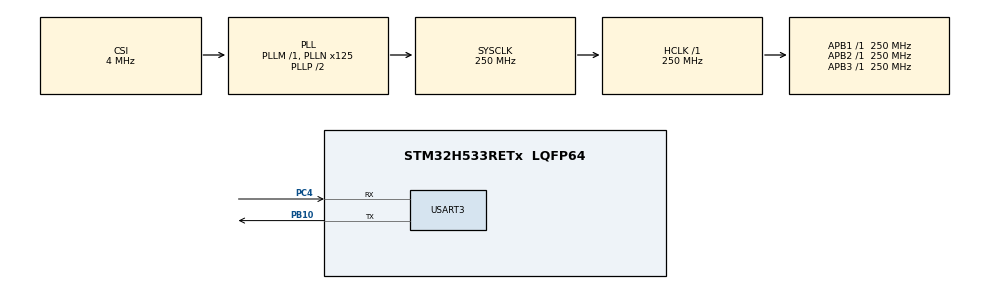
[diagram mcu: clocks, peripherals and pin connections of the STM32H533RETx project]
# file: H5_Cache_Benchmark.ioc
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CORTEX_M33_NS.userName=CORTEX_M33
Mcu.Family=STM32H5
Mcu.Name=STM32H533RETx
Mcu.Package=LQFP64
NUCLEO-H533RE.BUTTON=1
NUCLEO-H533RE.LD4=true
NUCLEO-H533RE.VCP=true
NVIC.EXTI13_IRQn=true\:0\:0\:false\:false\:true\:false\:true\:true
NVIC.PriorityGroup=NVIC_PRIORITYGROUP_4
PA13(JTMS/SWDIO).GPIO_Label=SWDIO
PA13(JTMS/SWDIO).Signal=DEBUG_JTMS-SWDIO
PA14(JTCK/SWCLK).GPIO_Label=SWCLK
PA14(JTCK/SWCLK).Signal=DEBUG_JTCK-SWCLK
PA15(JTDI).GPIO_Label=JTDI
PA15(JTDI).Signal=DEBUG_JTDI
PA2.Signal=USART2_TX
PA3.Signal=USART2_RX
PB10.Mode=Asynchronous
PB10.Signal=USART3_TX
PB3(JTDO/TRACESWO).GPIO_Label=SWO
PB3(JTDO/TRACESWO).Signal=DEBUG_JTDO-SWO
PC4.Mode=Asynchronous
PC4.Signal=USART3_RX
PH0-OSC_IN(PH0).Mode=HSE-External-Oscillator
PH0-OSC_IN(PH0).Signal=RCC_OSC_IN
PH1-OSC_OUT(PH1).Mode=HSE-External-Oscillator
PH1-OSC_OUT(PH1).Signal=RCC_OSC_OUT
ProjectManager.HeapSize=0x200
ProjectManager.StackSize=0x400
ProjectManager.TargetToolchain=CMake
RCC.ADCFreq_Value=250000000
RCC.AHBFreq_Value=250000000
RCC.APB1Freq_Value=250000000
RCC.APB1TimFreq_Value=250000000
RCC.APB2Freq_Value=250000000
RCC.APB2TimFreq_Value=250000000
RCC.APB3Freq_Value=250000000
RCC.CSI_VALUE=4000000
RCC.CortexFreq_Value=250000000
RCC.EPOD_VALUE=4000000
RCC.HCLKFreq_Value=250000000
RCC.HSE_VALUE=25000000
RCC.HSI48_VALUE=48000000
RCC.HSI_VALUE=64000000
RCC.LSE_VALUE=32768
RCC.LSIRC_VALUE=32000
RCC.PLL2FRACN=0
RCC.PLL3FRACN=0
RCC.PLLFRACN=0
RCC.PLLN=125
RCC.SYSCLKFreq_VALUE=250000000
RCC.SYSCLKSource=RCC_SYSCLKSOURCE_PLLCLK
RCC.USBFreq_Value=48000000
RCC.VCOOutputFreq_Value=500000000
USART3.VirtualMode-Asynchronous=VM_ASYNC
VP_BOOTPATH_VS_BOOTPATH.Mode=BP_Activate
VP_CORTEX_M33_NS_VS_Hclk.Mode=Hclk_Mode
VP_DCACHE1_VS_DCACHE.Mode=DCACHE_Activate
VP_ICACHE_VS_ICACHE.Mode=DefaultMode
VP_MEMORYMAP_VS_MEMORYMAP.Mode=CurAppReg
VP_NUCLEO-H533RE_VS_BSP_COMMON.Mode=COMMON
VP_PWR_VS_LPOM.Mode=PowerOptimisation
VP_PWR_VS_SECSignals.Mode=Security/Privilege
board=NUCLEO-H533RE

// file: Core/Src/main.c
/* USER CODE BEGIN Header */
/**
  ******************************************************************************
  * @file           : main.c
  * @brief          : Main program body
  ******************************************************************************
  * @attention
  *
  * Copyright (c) 2026 STMicroelectronics.
  * All rights reserved.
  *
  * This software is licensed under terms that can be found in the LICENSE file
  * in the root directory of this software component.
  * If no LICENSE file comes with this software, it is provided AS-IS.
  *
  ******************************************************************************
  */
/* USER CODE END Header */
#include "main.h"
#include <stdint.h>

/* USER CODE BEGIN Includes */
#include <string.h>
#include "cmsis_compiler.h"
#include <stdio.h>
/* USER CODE END Includes */

/* USER CODE BEGIN PD */
#define MATRIX_SIZE 32
#define T 8
/* USER CODE END PD */

COM_InitTypeDef BspCOMInit;

DCACHE_HandleTypeDef hdcache1;

UART_HandleTypeDef huart3;

/* USER CODE BEGIN PV */

float matA[MATRIX_SIZE * MATRIX_SIZE];
float matB[MATRIX_SIZE * MATRIX_SIZE];
float matC[MATRIX_SIZE * MATRIX_SIZE];

uint32_t standard_cycles = 0;
uint32_t tiled_cycles = 0;

/* USER CODE END PV */

void SystemClock_Config(void);
static void MX_GPIO_Init(void);
static void MX_DCACHE1_Init(void);
static void MX_ICACHE_Init(void);
static void MX_USART3_UART_Init(void);

/* USER CODE BEGIN PFP */
void DWT_Init(void);
void Matrix_Init(float* mat, uint32_t N);
void Matrix_Multiply_Standard(float* mat1, float* mat2, float* resultant, uint32_t N);
void Matrix_Multiply_tiling(float* a, float* b, float* c, uint32_t N);
/* USER CODE END PFP */

int main(void)
{

  /* MCU Configuration--------------------------------------------------------*/

  /* Reset of all peripherals, Initializes the Flash interface and the Systick. */
  HAL_Init();

  /* Configure the system clock */
  SystemClock_Config();

  /* Initialize all configured peripherals */
  MX_GPIO_Init();
  MX_DCACHE1_Init();
  MX_ICACHE_Init();
  MX_USART3_UART_Init();
  /* USER CODE BEGIN 2 */
  DWT_Init(); // Start the timer hardware

  // 1. Initialize Matrices with data (don't multiply zeros!)
  Matrix_Init(matA, MATRIX_SIZE);
  Matrix_Init(matB, MATRIX_SIZE);

  // 2. Test the Standard Version
  uint32_t start_std = DWT->CYCCNT;
  Matrix_Multiply_Standard(matA, matB, matC, MATRIX_SIZE);
  uint32_t end_std = DWT->CYCCNT;
  uint32_t standard_cycles = end_std - start_std;

  // 3. Test the Tiled Version
  uint32_t start_tiled = DWT->CYCCNT;
  Matrix_Multiply_tiling(matA, matB, matC, MATRIX_SIZE);
  uint32_t end_tiled = DWT->CYCCNT;
  uint32_t tiled_cycles = end_tiled - start_tiled;

  // Inside your main loop or test function
char buffer[100];
// Format: DATA,N,Standard,Tiled
sprintf(buffer, "DATA,%u,%u,%u\r\n", MATRIX_SIZE, standard_cycles, tiled_cycles);
HAL_UART_Transmit(&huart3, (uint8_t*)buffer, strlen(buffer), 100);
  /* USER CODE END 2 */

  /* Initialize leds */
  BSP_LED_Init(LED_GREEN);

  /* Initialize USER push-button, will be used to trigger an interrupt each time it's pressed.*/
  BSP_PB_Init(BUTTON_USER, BUTTON_MODE_EXTI);

  /* Initialize COM1 port (115200, 8 bits (7-bit data + 1 stop bit), no parity */
  BspCOMInit.BaudRate   = 115200;
  BspCOMInit.WordLength = COM_WORDLENGTH_8B;
  BspCOMInit.StopBits   = COM_STOPBITS_1;
  BspCOMInit.Parity     = COM_PARITY_NONE;
  BspCOMInit.HwFlowCtl  = COM_HWCONTROL_NONE;
  if (BSP_COM_Init(COM1, &BspCOMInit) != BSP_ERROR_NONE)
  {
    Error_Handler();
  }

  /* Infinite loop */
  while (1)
  {

  }
}

void SystemClock_Config(void)
{
  RCC_OscInitTypeDef RCC_OscInitStruct = {0};
  RCC_ClkInitTypeDef RCC_ClkInitStruct = {0};

  /** Configure the main internal regulator output voltage
  */
  __HAL_PWR_VOLTAGESCALING_CONFIG(PWR_REGULATOR_VOLTAGE_SCALE0);

  while(!__HAL_PWR_GET_FLAG(PWR_FLAG_VOSRDY)) {}

  /** Initializes the RCC Oscillators according to the specified parameters
  * in the RCC_OscInitTypeDef structure.
  */
  RCC_OscInitStruct.OscillatorType = RCC_OSCILLATORTYPE_CSI;
  RCC_OscInitStruct.CSIState = RCC_CSI_ON;
  RCC_OscInitStruct.CSICalibrationValue = RCC_CSICALIBRATION_DEFAULT;
  RCC_OscInitStruct.PLL.PLLState = RCC_PLL_ON;
  RCC_OscInitStruct.PLL.PLLSource = RCC_PLL1_SOURCE_CSI;
  RCC_OscInitStruct.PLL.PLLM = 1;
  RCC_OscInitStruct.PLL.PLLN = 125;
  RCC_OscInitStruct.PLL.PLLP = 2;
  RCC_OscInitStruct.PLL.PLLQ = 2;
  RCC_OscInitStruct.PLL.PLLR = 2;
  RCC_OscInitStruct.PLL.PLLRGE = RCC_PLL1_VCIRANGE_2;
  RCC_OscInitStruct.PLL.PLLVCOSEL = RCC_PLL1_VCORANGE_WIDE;
  RCC_OscInitStruct.PLL.PLLFRACN = 0;
  if (HAL_RCC_OscConfig(&RCC_OscInitStruct) != HAL_OK)
  {
    Error_Handler();
  }

  /** Initializes the CPU, AHB and APB buses clocks
  */
  RCC_ClkInitStruct.ClockType = RCC_CLOCKTYPE_HCLK|RCC_CLOCKTYPE_SYSCLK
                              |RCC_CLOCKTYPE_PCLK1|RCC_CLOCKTYPE_PCLK2
                              |RCC_CLOCKTYPE_PCLK3;
  RCC_ClkInitStruct.SYSCLKSource = RCC_SYSCLKSOURCE_PLLCLK;
  RCC_ClkInitStruct.AHBCLKDivider = RCC_SYSCLK_DIV1;
  RCC_ClkInitStruct.APB1CLKDivider = RCC_HCLK_DIV1;
  RCC_ClkInitStruct.APB2CLKDivider = RCC_HCLK_DIV1;
  RCC_ClkInitStruct.APB3CLKDivider = RCC_HCLK_DIV1;

  if (HAL_RCC_ClockConfig(&RCC_ClkInitStruct, FLASH_LATENCY_5) != HAL_OK)
  {
    Error_Handler();
  }

  /** Configure the programming delay
  */
  __HAL_FLASH_SET_PROGRAM_DELAY(FLASH_PROGRAMMING_DELAY_2);
}

static void MX_DCACHE1_Init(void)
{

  hdcache1.Instance = DCACHE1;
  hdcache1.Init.ReadBurstType = DCACHE_READ_BURST_WRAP;
  if (HAL_DCACHE_Init(&hdcache1) != HAL_OK)
  {
    Error_Handler();
  }

}

static void MX_ICACHE_Init(void)
{

  /** Enable instruction cache (default 2-ways set associative cache)
  */
  if (HAL_ICACHE_Enable() != HAL_OK)
  {
    Error_Handler();
  }

}

static void MX_USART3_UART_Init(void)
{

  huart3.Instance = USART3;
  huart3.Init.BaudRate = 115200;
  huart3.Init.WordLength = UART_WORDLENGTH_8B;
  huart3.Init.StopBits = UART_STOPBITS_1;
  huart3.Init.Parity = UART_PARITY_NONE;
  huart3.Init.Mode = UART_MODE_TX_RX;
  huart3.Init.HwFlowCtl = UART_HWCONTROL_NONE;
  huart3.Init.OverSampling = UART_OVERSAMPLING_16;
  huart3.Init.OneBitSampling = UART_ONE_BIT_SAMPLE_DISABLE;
  huart3.Init.ClockPrescaler = UART_PRESCALER_DIV1;
  huart3.AdvancedInit.AdvFeatureInit = UART_ADVFEATURE_NO_INIT;
  if (HAL_UART_Init(&huart3) != HAL_OK)
  {
    Error_Handler();
  }
  if (HAL_UARTEx_SetTxFifoThreshold(&huart3, UART_TXFIFO_THRESHOLD_1_8) != HAL_OK)
  {
    Error_Handler();
  }
  if (HAL_UARTEx_SetRxFifoThreshold(&huart3, UART_RXFIFO_THRESHOLD_1_8) != HAL_OK)
  {
    Error_Handler();
  }
  if (HAL_UARTEx_DisableFifoMode(&huart3) != HAL_OK)
  {
    Error_Handler();
  }

}

static void MX_GPIO_Init(void)
{

  /* GPIO Ports Clock Enable */
  __HAL_RCC_GPIOH_CLK_ENABLE();
  __HAL_RCC_GPIOC_CLK_ENABLE();
  __HAL_RCC_GPIOB_CLK_ENABLE();
  __HAL_RCC_GPIOA_CLK_ENABLE();

}

/* USER CODE BEGIN 4 */
void Matrix_Init(float* mat, uint32_t N) {
    for (uint32_t i = 0; i < N * N; i++) {
        // Fill with simple fractional numbers to keep the FPU busy
        mat[i] = (float)i * 0.123f;
    }
}

//Standard matrix multiplication with no tiling used as control for cache analysis
#define T 8
void Matrix_Multiply_Standard(float* mat1, float* mat2, float* resultant, uint32_t N){
  if(!mat1 || !mat2 || !resultant){
    return; //return if null pointer
  }

  memset(resultant, 0, N * N * sizeof(float)); // Clear C once at the very start

  for(uint32_t rows = 0; rows < N; rows++){ //mat1 rows
    for(uint32_t cols = 0; cols < N; cols++){  //mat2 cols
      float sum = 0.0f;
      for(uint32_t k = 0; k < N; k++){ //in pointer addition moves column multiplication move down row
          sum += mat1[rows * N + k] * mat2[k * N + cols];
      }
      resultant[rows * N + cols] = sum;
    }
  }
}

//matrix using tiling method
void Matrix_Multiply_tiling(float* a, float* b, float* c, uint32_t N){
  if(!a || !b || !c){
    return;
  }

  memset(c, 0, N * N * sizeof(float)); // Clear C once at the very start

  for(uint32_t i_tile = 0; i_tile <  N; i_tile+=T){
    for(uint32_t j_tile = 0; j_tile < N; j_tile+=T){
      for(uint32_t k_tile = 0; k_tile < N; k_tile+=T){

        for(uint32_t i = i_tile; i < i_tile+T; i++){
          for(uint32_t j = j_tile; j < j_tile+T; j++){
            float sum = 0.0f;
            for(uint32_t k = k_tile; k < k_tile+T; k++){
              sum += a[i * N + k] * b[k * N + j];
            }
            c[i * N + j] += sum;
          }
        }
      }
    }
  }
}

void DWT_Init(void) {
    // 1. Enable the Trace system
    CoreDebug->DEMCR |= CoreDebug_DEMCR_TRCENA_Msk;

    // 2. Reset the cycle counter
    DWT->CYCCNT = 0;

    // 3. Enable the cycle counter
    DWT->CTRL |= DWT_CTRL_CYCCNTENA_Msk;
}
/* USER CODE END 4 */

void Error_Handler(void)
{
  __disable_irq();
  while (1)
  {
  }
}
